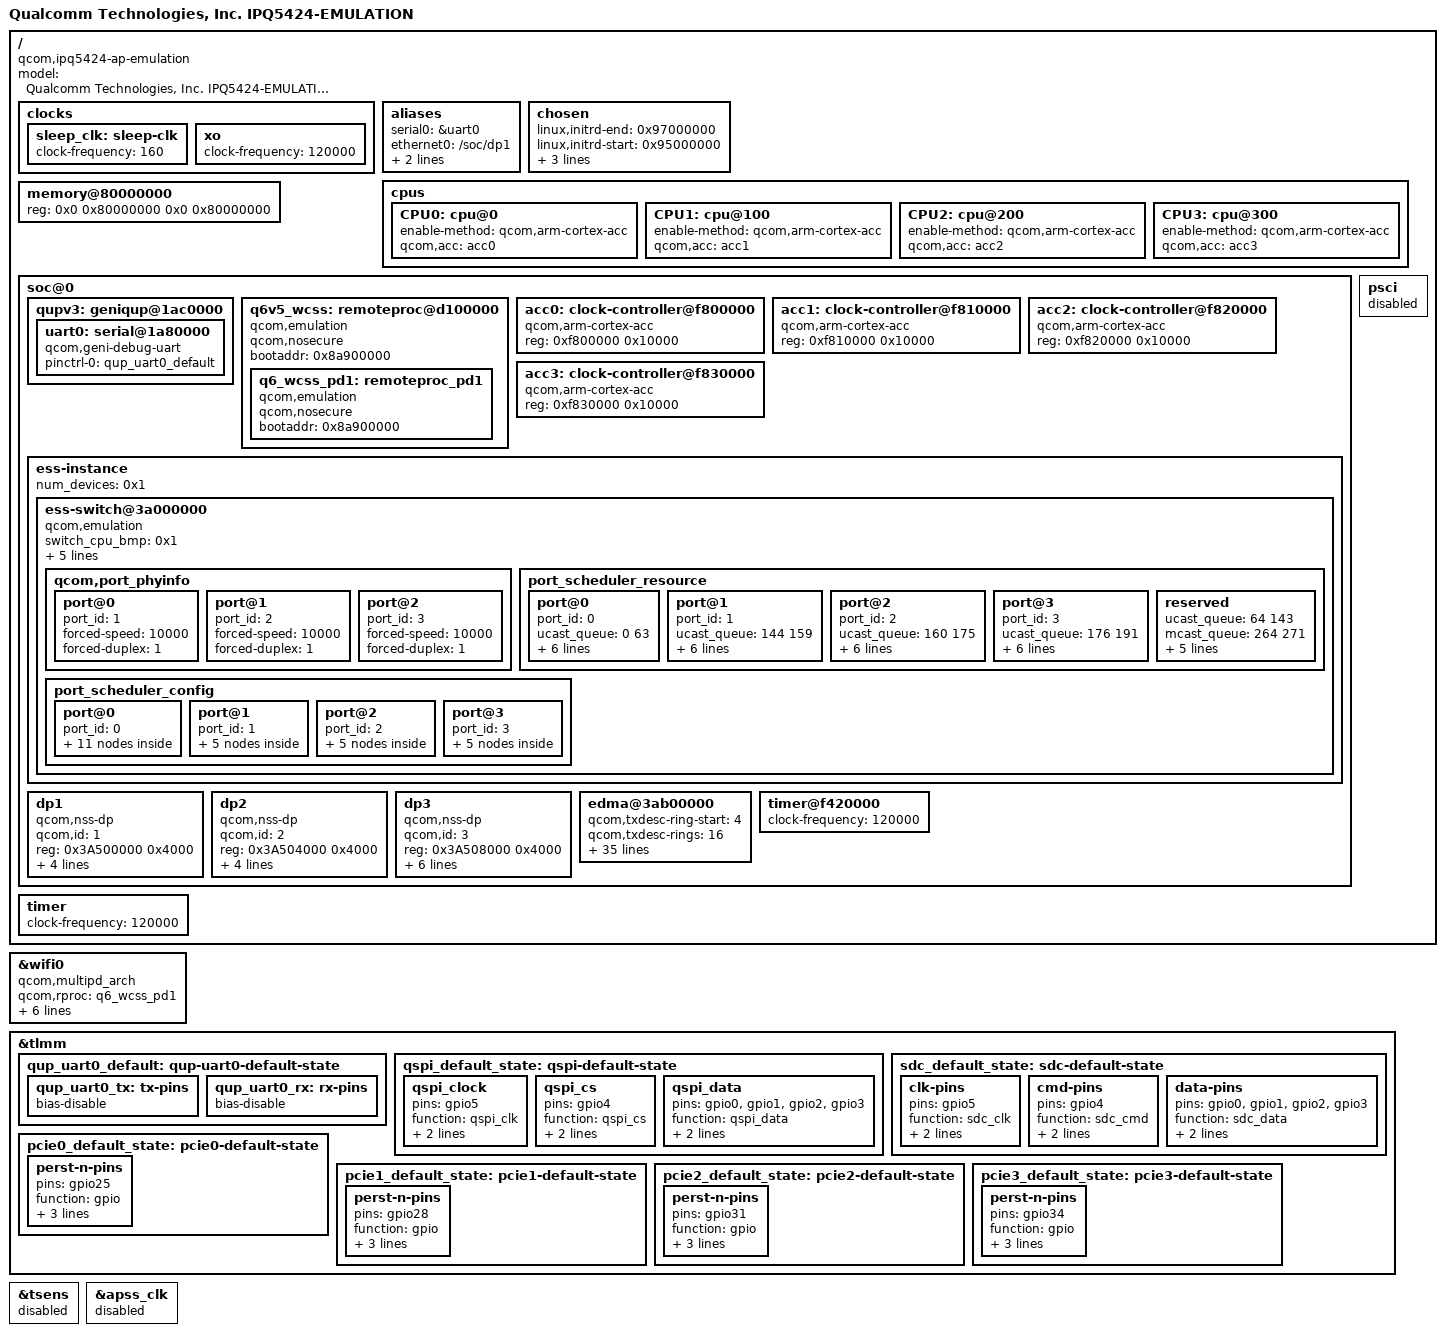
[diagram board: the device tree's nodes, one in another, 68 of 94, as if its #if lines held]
// SPDX-License-Identifier: (GPL-2.0+ OR BSD-3-Clause)
/*
 * IPQ5424 Emulation SSOC device tree source
 *
 * Copyright (c) 2020-2021 The Linux Foundation. All rights reserved.
 * Copyright (c) 2022-2024 Qualcomm Innovation Center, Inc. All rights reserved.
 */

/dts-v1/;

#include "ipq5424.dtsi"
#ifdef __IPQ_MEM_PROFILE_512_MB__
#include "ipq5424-512MB-default-memory.dtsi"
#else
#include "ipq5424-default-memory.dtsi"
#endif

/ {
	model = "Qualcomm Technologies, Inc. IPQ5424-EMULATION";
	compatible = "qcom,ipq5424-ap-emulation", "qcom,ipq5424";

	/delete-node/ firmware;
	/delete-node/ qti,tzlog;
	/delete-node/ ctx-save;

	/*Timer freq for rumi = timer freq / 200*/
	clocks {
		sleep_clk: sleep-clk {
			clock-frequency = <160>;
		};

		xo: xo {
			clock-frequency = <120000>;
		};
	};

	aliases {
		serial0 = &uart0;
		ethernet0 = "/soc/dp1";
		ethernet1 = "/soc/dp2";
		ethernet2 = "/soc/dp3";
	};

	chosen {
		linux,initrd-end = <0x97000000>;
		linux,initrd-start = <0x95000000>;
		bootargs = "root=/dev/ram0 rw init=/init clk_ignore_unused maxcpus=2";
		stdout-path = "serial0";
	};

	cpus: cpus {
		CPU0: cpu@0 {
			enable-method = "qcom,arm-cortex-acc";
			qcom,acc = <&acc0>;
		};

		CPU1: cpu@100 {
			enable-method = "qcom,arm-cortex-acc";
			qcom,acc = <&acc1>;
		};

		CPU2: cpu@200 {
			enable-method = "qcom,arm-cortex-acc";
			qcom,acc = <&acc2>;
		};

		CPU3: cpu@300 {
			enable-method = "qcom,arm-cortex-acc";
			qcom,acc = <&acc3>;
		};
	};

	memory@80000000 {
		reg = <0x0 0x80000000 0x0 0x80000000>;
	};

	soc@0 {
		qupv3: geniqup@1ac0000 {
			status = "okay";

			/* On emulation platform, uart0 is the debug uart */
			uart0: serial@1a80000 {
				compatible = "qcom,geni-debug-uart";
				pinctrl-0 = <&qup_uart0_default>;
				pinctrl-names = "default";
				status = "okay";
			};
		};

#ifdef __QCOM_NON_SECURE_PIL__
		q6v5_wcss: remoteproc@d100000 {
			qcom,emulation;
			qcom,nosecure;
			bootaddr = <0x8a900000>;
			status = "okay";
			q6_wcss_pd1: remoteproc_pd1 {
				qcom,emulation;
				qcom,nosecure;
				bootaddr = <0x8a900000>;
			};
		};
#endif

		acc0: clock-controller@f800000 {
			compatible = "qcom,arm-cortex-acc";
			reg = <0xf800000 0x10000>;
		};

		acc1: clock-controller@f810000 {
			compatible = "qcom,arm-cortex-acc";
			reg = <0xf810000 0x10000>;
		};

		acc2:clock-controller@f820000 {
			compatible = "qcom,arm-cortex-acc";
			reg = <0xf820000 0x10000>;
		};

		acc3:clock-controller@f830000 {
			compatible = "qcom,arm-cortex-acc";
			reg = <0xf830000 0x10000>;
		};

		ess-instance {
			num_devices = <0x1>;
			ess-switch@3a000000 {
				qcom,emulation; /* RUMI ENV */
				switch_cpu_bmp = <0x1>;  /* cpu port bitmap */
				switch_lan_bmp = <0x6>; /* lan port bitmap */
				switch_wan_bmp = <0x8>; /* wan port bitmap */
				switch_mac_mode = <0xd>; /* mac mode for uniphy instance0*/
				switch_mac_mode1 = <0xd>; /* mac mode for uniphy instance1*/
				switch_mac_mode2 = <0xd>; /* mac mode for uniphy instance2*/
				qcom,port_phyinfo {
					port@0 {
						port_id = <1>;
						forced-speed = <10000>;
						forced-duplex = <1>;
					};
					port@1 {
						port_id = <2>;
						forced-speed = <10000>;
						forced-duplex = <1>;
					};
					port@2 {
						port_id = <3>;
						forced-speed = <10000>;
						forced-duplex = <1>;
					};
				};
				port_scheduler_resource {
					port@0 {
						port_id = <0>;
						ucast_queue = <0 63>;
						mcast_queue = <256 263>;
						l0sp = <0 0>;
						l0cdrr = <0 7>;
						l0edrr = <0 7>;
						l1cdrr = <0 0>;
						l1edrr = <0 0>;
					};
					port@1 {
						port_id = <1>;
						ucast_queue = <144 159>;
						mcast_queue = <272 275>;
						l0sp = <36 39>;
						l0cdrr = <48 63>;
						l0edrr = <48 63>;
						l1cdrr = <8 11>;
						l1edrr = <8 11>;
					};
					port@2 {
						port_id = <2>;
						ucast_queue = <160 175>;
						mcast_queue = <276 279>;
						l0sp = <40 43>;
						l0cdrr = <64 79>;
						l0edrr = <64 79>;
						l1cdrr = <12 15>;
						l1edrr = <12 15>;
					};
					port@3 {
						port_id = <3>;
						ucast_queue = <176 191>;
						mcast_queue = <280 283>;
						l0sp = <44 47>;
						l0cdrr = <80 95>;
						l0edrr = <80 95>;
						l1cdrr = <16 19>;
						l1edrr = <16 19>;
					};
					reserved {
						ucast_queue = <64 143>;
						mcast_queue = <264 271>;
						l0sp = <1 35>;
						l0cdrr = <8 47>;
						l0edrr = <8 47>;
						l1cdrr = <1 7>;
						l1edrr = <1 7>;
					};
				};
				port_scheduler_config {
					port@0 {
						port_id = <0>;
						l1scheduler {
							group@0 {
								/* L0 SP */
								sp = <0>;
								/* cpri cdrr epri edrr */
								cfg = <0 0 0 0>;
							};
						};
						l0scheduler {
							group@0 {
								/* unicast queue */
								ucast_queue = <0>;
								ucast_loop_pri = <8>;
								/* multicast queue */
								mcast_queue = <256>;
								/* sp cpri cdrr epri edrr */
								cfg = <0 0 0 0 0>;
							};
							group@1 {
								ucast_queue = <8>;
								ucast_loop_pri = <8>;
								mcast_queue = <257>;
								cfg = <0 0 0 0 0>;
							};
							group@2 {
								ucast_queue = <16>;
								ucast_loop_pri = <8>;
								mcast_queue = <258>;
								cfg = <0 0 0 0 0>;
							};
							group@3 {
								ucast_queue = <24>;
								ucast_loop_pri = <8>;
								mcast_queue = <259>;
								cfg = <0 0 0 0 0>;
							};
							group@4 {
								ucast_queue = <32>;
								ucast_loop_pri = <8>;
								mcast_queue = <260>;
								cfg = <0 0 0 0 0>;
							};
							group@5 {
								ucast_queue = <40>;
								ucast_loop_pri = <8>;
								mcast_queue = <261>;
								cfg = <0 0 0 0 0>;
							};
							group@6 {
								ucast_queue = <48>;
								ucast_loop_pri = <8>;
								mcast_queue = <262>;
								cfg = <0 0 0 0 0>;
							};
							group@7 {
								ucast_queue = <56>;
								ucast_loop_pri = <8>;
								mcast_queue = <263>;
								cfg = <0 0 0 0 0>;
							};
						};
					};
					port@1 {
						port_id = <1>;
						l1scheduler {
							group@0 {
								sp = <36>;
								cfg = <0 8 0 8>;
							};
							group@1 {
								sp = <37>;
								cfg = <0 8 0 8>;
							};
						};
						l0scheduler {
							group@0 {
								ucast_queue = <144>;
								ucast_loop_pri = <16>;
								mcast_queue = <272>;
								mcast_loop_pri = <4>;
								cfg = <36 0 48 0 48>;
							};
						};
					};
					port@2 {
						port_id = <2>;
						l1scheduler {
							group@0 {
								sp = <40>;
								cfg = <0 12 0 12>;
							};
							group@1 {
								sp = <41>;
								cfg = <0 12 0 12>;
							};
						};
						l0scheduler {
							group@0 {
								ucast_queue = <160>;
								ucast_loop_pri = <16>;
								mcast_queue = <276>;
								mcast_loop_pri = <4>;
								cfg = <40 0 64 0 64>;
							};
						};
					};
					port@3 {
						port_id = <3>;
						l1scheduler {
							group@0 {
								sp = <44>;
								cfg = <0 16 0 16>;
							};
							group@1 {
								sp = <45>;
								cfg = <0 16 0 16>;
							};
						};
						l0scheduler {
							group@0 {
								ucast_queue = <176>;
								ucast_loop_pri = <16>;
								mcast_queue = <280>;
								mcast_loop_pri = <4>;
								cfg = <44 0 80 0 80>;
							};
						};
					};
				};
			};
		};

		dp1 {
			device_type = "network";
			compatible = "qcom,nss-dp";
			qcom,id = <1>;
			reg = <0x3A500000 0x4000>;
			qcom,mactype = <1>;
			local-mac-address = [000000000000];
			qcom,phy-mdio-addr = <0>;
			phy-mode = "sgmii";
		};

		dp2 {
			device_type = "network";
			compatible = "qcom,nss-dp";
			qcom,id = <2>;
			reg = <0x3A504000 0x4000>;
			qcom,mactype = <1>;
			local-mac-address = [000000000000];
			qcom,phy-mdio-addr = <0>;
			phy-mode = "sgmii";
		};

		dp3 {
			device_type = "network";
			compatible = "qcom,nss-dp";
			qcom,id = <3>;
			reg = <0x3A508000 0x4000>;
			qcom,mactype = <1>;
			local-mac-address = [000000000000];
			qcom,phy-mdio-addr = <0>;
			phy-mode = "sgmii";
			qcom,mht-dev = <1>;
			qcom,is_switch_connected = <1>;
		};

		/* EDMA host driver configuration for the board */
		edma@3ab00000 {
			qcom,txdesc-ring-start = <4>;		/* Tx desc ring start ID */
			qcom,txdesc-rings = <16>;		/* Total number of Tx desc rings to be provisioned */
			qcom,mht-txdesc-rings = <12>;		/* Extra Tx desc rings to be provisioned for MHT SW ports */
			qcom,txcmpl-ring-start = <4>;		/* Tx complete ring start ID */
			qcom,txcmpl-rings = <16>;		/* Total number of Tx complete rings to be provisioned */
			qcom,mht-txcmpl-rings = <12>;		/* Extra Tx complete rings to be provisioned for mht sw ports. */
			qcom,rxfill-ring-start = <4>;		/* Rx fill ring start ID */
			qcom,rxfill-rings = <4>;		/* Total number of Rx fill rings to be provisioned */
			qcom,rxdesc-ring-start = <20>;		/* Rx desc ring start ID */
			qcom,rxdesc-rings = <4>;		/* Total number of Rx desc rings to be provisioned */
			qcom,rx-page-mode = <0>;		/* Rx fill ring page mode */
			qcom,tx-map-priority-level = <1>;	/* Tx priority level per port */
			qcom,rx-map-priority-level = <1>;	/* Rx priority level per core */
			qcom,ppeds-num = <4>;			/* Number of PPEDS nodes */
			/* PPE-DS node format: <Rx-fill Tx-cmpl Rx Tx Queue-base Queue-count> */
			qcom,ppeds-map = <1 1 1 1 32 8>,	/* PPEDS Node #0 ring and queue map */
					<2 2 2 2 40 8>,		/* PPEDS Node #1 ring and queue map */
					<3 3 3 3 48 8>,		/* PPEDS Node #2 ring and queue map */
					<0 0 0 0 56 8>;		/* PPEDS Node #3 ring and queue map */
			qcom,txdesc-map = <4 5 6 7>,		/* Port1 per-core Tx ring map */
					<8 9 10 11>,		/* Port2 per-core Tx ring map */
					<12 13 14 15>,		/* MHT-Port1 per-core Tx ring map */
					<16 17 18 19>,		/* MHT-Port2 per-core Tx ring map */
					<20 21 22 23>,		/* MHT-Port3 per-core Tx ring map */
					<24 25 26 27>,		/* MHT-Port4 per-core Tx ring map */
					<28 29 30 31>;		/* Used only for packets from VP */
			qcom,txdesc-fc-grp-map = <1 2 3 4 5 6>;	/* Per GMAC flow control group map */
			qcom,rxfill-map = <4 5 6 7>;		/* Per-core Rx fill ring map */
			qcom,rxdesc-map = <20 21 22 23>;	/* Per-core Rx desc ring map */
			qcom,rx-queue-start = <0>;		/* Rx queue start */
			qcom,rx-ring-queue-map = <0 8 16 24>,	/* Priority 0 queues per-core Rx ring map */
						<1 9 17 25>,	/* Priority 1 queues per-core Rx ring map */
						<2 10 18 26>,	/* Priority 2 queues per-core Rx ring map */
						<3 11 19 27>,	/* Priority 3 queues per-core Rx ring map */
						<4 12 20 28>,	/* Priority 4 queues per-core Rx ring map */
						<5 13 21 29>,	/* Priority 5 queues per-core Rx ring map */
						<6 14 22 30>,	/* Priority 6 queues per-core Rx ring map */
						<7 15 23 31>;	/* Priority 7 queues per-core Rx ring map */
			interrupts = <0 286 4>,			/* Tx complete ring id #4 IRQ info */
					<0 287 4>,		/* Tx complete ring id #5 IRQ info */
					<0 288 4>,		/* Tx complete ring id #6 IRQ info */
					<0 289 4>,		/* Tx complete ring id #7 IRQ info */
					<0 290 4>,		/* Tx complete ring id #8 IRQ info */
					<0 291 4>,		/* Tx complete ring id #9 IRQ info */
					<0 292 4>,		/* Tx complete ring id #10 IRQ info */
					<0 293 4>,		/* Tx complete ring id #11 IRQ info */
					<0 294 4>,		/* Tx complete ring id #12 IRQ info */
					<0 295 4>,		/* Tx complete ring id #13 IRQ info */
					<0 296 4>,		/* Tx complete ring id #14 IRQ info */
					<0 297 4>,		/* Tx complete ring id #15 IRQ info */
					<0 298 4>,		/* Tx complete ring id #16 IRQ info */
					<0 299 4>,		/* Tx complete ring id #17 IRQ info */
					<0 300 4>,		/* Tx complete ring id #18 IRQ info */
					<0 301 4>,		/* Tx complete ring id #19 IRQ info */
					<0 270 4>,		/* Rx desc ring id #20 IRQ info */
					<0 271 4>,		/* Rx desc ring id #21 IRQ info */
					<0 272 4>,		/* Rx desc ring id #22 IRQ info */
					<0 273 4>,		/* Rx desc ring id #23 IRQ info */
					<0 314 4>,		/* Misc error IRQ info */
					<0 278 4>,		/* RxFill ring id #4 IRQ info */
					<0 279 4>,		/* RxFill ring id #5 IRQ info */
					<0 280 4>,		/* RxFill ring id #6 IRQ info */
					<0 281 4>,		/* RxFill ring id #7 IRQ info */
					<0 283 4>,		/* PPEDS Node #0(TxComp ring id #1) TxComplete IRQ info */
					<0 251 4>,		/* PPEDS Node #0(Rx Desc ring id #1) Rx Desc IRQ info */
					<0 275 4>,		/* PPEDS Node #0(RxFill Desc ring id #1) Rx Fill IRQ info */
					<0 284 4>,		/* PPEDS Node #1(TxComp ring id #2) TxComplete IRQ info */
					<0 252 4>,		/* PPEDS Node #1(Rx Desc ring id #2) Rx Desc IRQ info */
					<0 276 4>,		/* PPEDS Node #1(RxFill Desc ring id #2) Rx Fill IRQ info */
					<0 285 4>,		/* PPEDS Node #2(TxComp ring id #3) TxComplete IRQ info */
                                        <0 253 4>,		/* PPEDS Node #2(Rx Desc ring id #3) Rx Desc IRQ info */
                                        <0 277 4>,		/* PPEDS Node #2(RxFill Desc ring id #3) Rx Fill IRQ info */
					<0 282 4>,		/* PPEDS Node #3(TxComp ring id #0) TxComplete IRQ info */
					<0 250 4>,		/* PPEDS Node #3(Rx Desc ring id #0) Rx Desc IRQ info */
					<0 274 4>,		/* PPEDS Node #3(RxFill Desc ring id #0) Rx Fill IRQ info */
					<0 302 4>,		/* MHT port Tx complete ring id #20 IRQ info */
                                        <0 303 4>,		/* MHT port Tx complete ring id #21 IRQ info */
                                        <0 304 4>,		/* MHT port Tx complete ring id #22 IRQ info */
                                        <0 305 4>,		/* MHT port Tx complete ring id #23 IRQ info */
					<0 306 4>,		/* MHT port Tx complete ring id #24 IRQ info */
					<0 307 4>,		/* MHT port Tx complete ring id #25 IRQ info */
					<0 308 4>,		/* MHT port Tx complete ring id #26 IRQ info */
					<0 309 4>,		/* MHT port Tx complete ring id #27 IRQ info */
					<0 310 4>,		/* MHT port Tx complete ring id #28 IRQ info */
					<0 311 4>,		/* MHT port Tx complete ring id #29 IRQ info */
					<0 312 4>,		/* MHT port Tx complete ring id #30 IRQ info */
					<0 313 4>;		/* MHT port Tx complete ring id #31 IRQ info */
                };

		/* Timer freq for rumi = timer freq / 200 */
		timer@f420000 {
			clock-frequency = <120000>;
		};
	};

	/* Timer freq for rumi = timer freq / 200 */
	timer {
		clock-frequency = <120000>;
	};

	psci {
		status = "disabled";
	};
};

&wifi0 {
#ifdef __QCOM_NON_SECURE_PIL__
	qcom,multipd_arch;
	qcom,rproc = <&q6_wcss_pd1>;
	qcom,rproc_rpd = <&q6v5_wcss>;
	qcom,userpd-subsys-name = "q6v5_wcss_userpd1";
#else
	qcom,rproc = <&q6v5_wcss>;
#endif
	qcom,tgt-mem-mode = <0>;
	memory-region = <&q6_region>;
	qcom,board_id = <0x10>;
	hw_link_id = <0 0>;
	status = "okay";
};

&tlmm {
	qup_uart0_default: qup-uart0-default-state {
		qup_uart0_tx: tx-pins {
			bias-disable;
		};

		qup_uart0_rx: rx-pins {
			bias-disable;
		};
	};

	qspi_default_state: qspi-default-state {
		qspi_clock {
			pins = "gpio5";
			function = "qspi_clk";
			drive-strength = <8>;
			bias-pull-down;
		};

		qspi_cs {
			pins = "gpio4";
			function = "qspi_cs";
			drive-strength = <8>;
			bias-pull-up;
		};

		qspi_data {
			pins = "gpio0", "gpio1", "gpio2", "gpio3";
			function = "qspi_data";
			drive-strength = <8>;
			bias-pull-down;
		};
	};

	sdc_default_state: sdc-default-state {
		clk-pins {
			pins = "gpio5";
			function = "sdc_clk";
			drive-strength = <8>;
			bias-disable;
		};

		cmd-pins {
			pins = "gpio4";
			function = "sdc_cmd";
			drive-strength = <8>;
			bias-pull-up;
		};

		data-pins {
			pins = "gpio0", "gpio1", "gpio2", "gpio3";
			function = "sdc_data";
			drive-strength = <8>;
			bias-pull-up;
		};
	};

	pcie0_default_state: pcie0-default-state {
		perst-n-pins {
			pins = "gpio25";
			function = "gpio";
			drive-strength = <2>;
			bias-pull-down;
			output-low;
		};
	};

	pcie1_default_state: pcie1-default-state {
		perst-n-pins {
			pins = "gpio28";
			function = "gpio";
			drive-strength = <2>;
			bias-pull-down;
			output-low;
		};
	};

	pcie2_default_state: pcie2-default-state {
		perst-n-pins {
			pins = "gpio31";
			function = "gpio";
			drive-strength = <2>;
			bias-pull-down;
			output-low;
		};
	};

	pcie3_default_state: pcie3-default-state {
		perst-n-pins {
			pins = "gpio34";
			function = "gpio";
			drive-strength = <2>;
			bias-pull-down;
			output-low;
		};
	};
};

&tsens {
	status = "disabled";
};

&apss_clk {
	status = "disabled";
};
